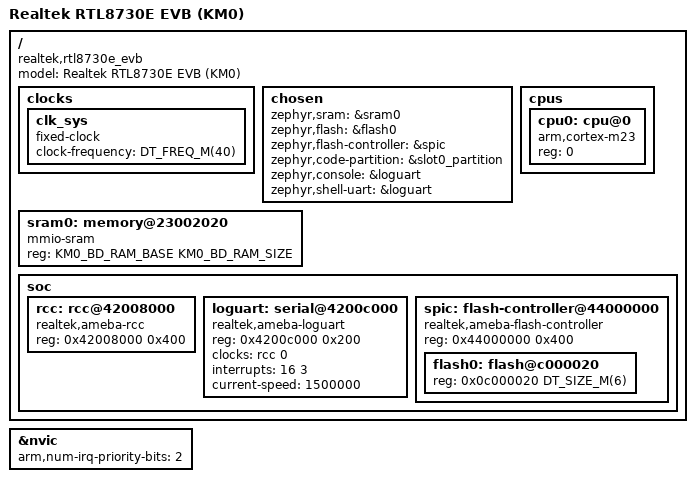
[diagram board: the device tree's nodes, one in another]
/*
 * Copyright (c) 2026 Realtek Semiconductor Corp.
 *
 * SPDX-License-Identifier: Apache-2.0
 *
 * RTL8730E EVB - KM0 low-power core (Real-M200, Cortex-M23 / Armv8-M baseline).
 *
 * KM0 lives in the LS (low-speed) domain.  KM4 boots first and releases KM0
 * (LSYS_BIT_BOOT_KM0_RUN); KM0 then runs its own image (image2).
 *
 * Memory (project_lp ameba_layout.ld):
 *   KM0_BD_RAM   0x23002020 .. 0x2301FD00  (~119 KB main SRAM)  -> zephyr,sram
 *   KM0_IMG2_XIP 0x0C000020 ..             (flash XIP window)    -> zephyr,flash
 * The image runs from SRAM (CONFIG_XIP=n), loaded by the LP bootloader, so the
 * flash node describes the KM0 XIP logic window only for the flash driver and
 * the code-partition metadata.
 */

/dts-v1/;

#include <arm/armv8-m.dtsi>
#include <mem.h>
#include <freq.h>
#include "rtl8730e_evb_partitions.h"

/* KM0 main SRAM (KM0_BD_RAM): base 0x23002020, len 0x2301FD00 - 0x23002020. */
#define KM0_BD_RAM_BASE  0x23002020
#define KM0_BD_RAM_SIZE  (0x2301FD00 - 0x23002020)

/ {
	model = "Realtek RTL8730E EVB (KM0)";
	compatible = "realtek,rtl8730e_evb";

	clocks {
		#address-cells = <1>;
		#size-cells = <1>;

		/* KM0 LP core clock: XTAL 40 MHz (bootloader_lp selects LP XTAL). */
		clk_sys: clk_sys {
			#clock-cells = <0>;
			compatible = "fixed-clock";
			clock-frequency = <DT_FREQ_M(40)>;
		};
	};

	chosen {
		zephyr,sram             = &sram0;
		zephyr,flash            = &flash0;
		zephyr,flash-controller = &spic;
		zephyr,code-partition   = &slot0_partition;
		zephyr,console          = &loguart;
		zephyr,shell-uart       = &loguart;
	};

	sram0: memory@23002020 {
		compatible = "mmio-sram";
		reg = <KM0_BD_RAM_BASE KM0_BD_RAM_SIZE>;
	};

	cpus {
		#address-cells = <1>;
		#size-cells = <0>;

		cpu0: cpu@0 {
			device_type = "cpu";
			compatible = "arm,cortex-m23";
			reg = <0>;
		};
	};

	soc {
		rcc: rcc@42008000 {
			compatible = "realtek,ameba-rcc";
			reg = <0x42008000 0x400>;
			#clock-cells = <1>;
			status = "okay";
		};

		/* Shared LOGUART @ 0x4200C000.  On the KM0 (LP) NVIC the LOGUART
		 * source is UART_LOG_IRQ = 16 (differs from the KM4 side, where
		 * it is 8) -- see ameba_vector.h LPIRQn_enum.
		 */
		loguart: serial@4200c000 {
			compatible = "realtek,ameba-loguart";
			reg = <0x4200c000 0x200>;
			clocks = <&rcc 0>;
			interrupts = <16 3>;
			current-speed = <1500000>;
			status = "okay";
		};

		/* SPIC flash controller -- KM0 XIP logic window (KM0_IMG2_XIP). */
		spic: flash-controller@44000000 {
			compatible = "realtek,ameba-flash-controller";
			reg = <0x44000000 0x400>;
			#address-cells = <1>;
			#size-cells = <1>;
			status = "okay";

			flash0: flash@c000020 {
				reg = <0x0c000020 DT_SIZE_M(6)>;
#include "rtl8730e_evb_partitions.dtsi"
			};
		};
	};
};

/* KM0 NVIC implements 2 priority bits (__NVIC_PRIO_BITS = 2, core_cm23_km0.h). */
&nvic {
	arm,num-irq-priority-bits = <2>;
};
